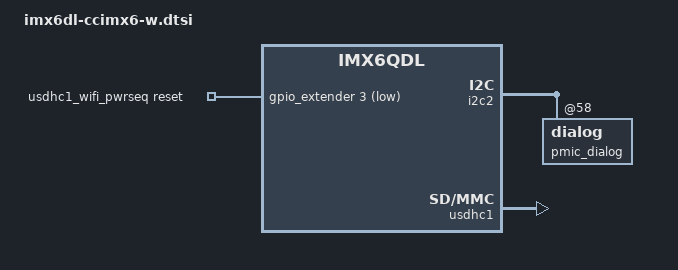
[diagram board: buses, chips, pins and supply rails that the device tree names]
/*
 * Copyright (C) 2015-2025, Digi International Inc.
 *
 * The code contained herein is licensed under the GNU General Public
 * License. You may obtain a copy of the GNU General Public License
 * Version 2 or later at the following locations:
 *
 * http://www.opensource.org/licenses/gpl-license.html
 * http://www.gnu.org/copyleft/gpl.html
 */

/* ConnectCore 6 (common) */
#include "imx6qdl-ccimx6.dtsi"

/ {
	usdhc1_wifi_pwrseq: usdhc1-wifi-pwrseq {
		compatible = "mmc-pwrseq-simple";
		post-power-on-delay-ms = <5>;
		reset-gpios = <&gpio_extender 3 GPIO_ACTIVE_LOW>; /* WLAN_PWD */
	};

	wireless {
		compatible = "atheros,ath6kl";
		ath6kl-p2p-enable;
		ath6kl-softmac-enable;
		/* U-Boot will fill in the MAC address here */
	};
};

&i2c2 {
	pmic_dialog: dialog@58 {
		regulators {
			bio {
				regulator-always-on;
			};

			ldo2 {
				regulator-always-on;
			};
		};
	};
};

/* USDHC1 (Wireless) */
&usdhc1 {
	no-1-8-v;
	mmc-pwrseq = <&usdhc1_wifi_pwrseq>;
	status = "okay";
};
